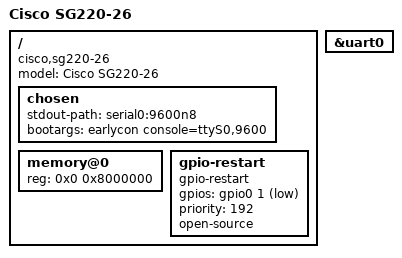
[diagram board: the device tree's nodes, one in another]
// SPDX-License-Identifier: GPL-2.0-or-later OR BSD-2-Clause

/dts-v1/;

#include "rtl838x.dtsi"

#include <dt-bindings/gpio/gpio.h>

/ {
	model = "Cisco SG220-26";
	compatible = "cisco,sg220-26", "realtek,rtl8382-soc";

	chosen {
		stdout-path = "serial0:9600n8";
		bootargs = "earlycon console=ttyS0,9600";
	};

	memory@0 {
		device_type = "memory";
		reg = <0x0 0x8000000>;
	};

	gpio-restart {
		compatible = "gpio-restart";
		gpios = <&gpio0 1 GPIO_ACTIVE_LOW>;
		priority = <192>;
		open-source;
	};
};

&uart0 {
	status = "okay";
};
